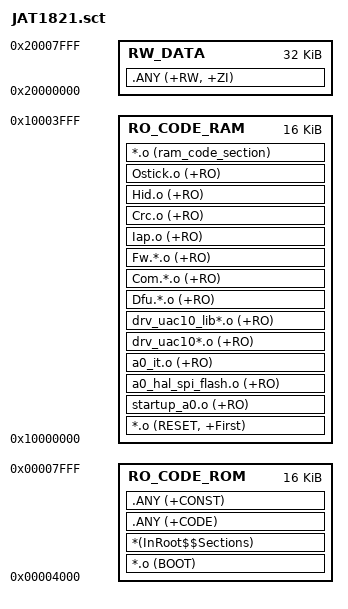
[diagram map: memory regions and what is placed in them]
#! armcc -E
; *************************************************************
; *** Scatter-Loading Description File generated by uVision ***
; *************************************************************


LR_ROM0  0x00000000  0x00004000
{
	RO_CODE_RAM  0x10000000  0x00004000
	{
		*.o (RESET, +First)
		startup_a0.o (+RO)
		a0_hal_spi_flash.o (+RO)
		a0_it.o (+RO)

		;lib_drv_uac10.o (+RO)
		;app_usb_device_uac10.o (+RO)
        drv_uac10*.o (+RO)
		drv_uac10_lib*.o (+RO)
		
		Dfu.*.o (+RO)
		Com.*.o (+RO)
		Fw.*.o (+RO)
		
		Iap.o (+RO)
		Crc.o (+RO)
		Hid.o (+RO)
		Ostick.o (+RO)
		
		*.o (ram_code_section)
	}
}


LR_ROM1  0x00004000  0x00004000
{
	RO_CODE_ROM  0x00004000  0x0004000
	{
		*.o (BOOT)
		*(InRoot$$Sections)
		.ANY (+CODE)
		.ANY (+CONST)
	}

	RW_DATA  0x20000000  0x00008000
	{
		.ANY (+RW, +ZI)
	}
}
